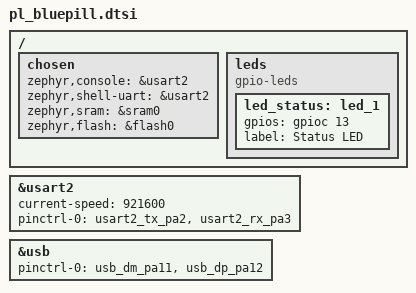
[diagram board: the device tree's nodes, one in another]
#include <st/f1/stm32f103c(8-b)tx-pinctrl.dtsi>

/ {
  chosen {
    zephyr,console = &usart2;
    zephyr,shell-uart = &usart2;
    zephyr,sram = &sram0;
    zephyr,flash = &flash0;
  };

  leds {
    compatible = "gpio-leds";
    led_status: led_1 {
      gpios = <&gpioc 13 0>;
      label = "Status LED";
    };
  };
};

&usart2 {
  current-speed = <921600>;
  pinctrl-0 = <&usart2_tx_pa2 &usart2_rx_pa3>;
  status = "okay";
};

&usb {
  pinctrl-0 = <&usb_dm_pa11 &usb_dp_pa12>;
  status = "okay";
};
